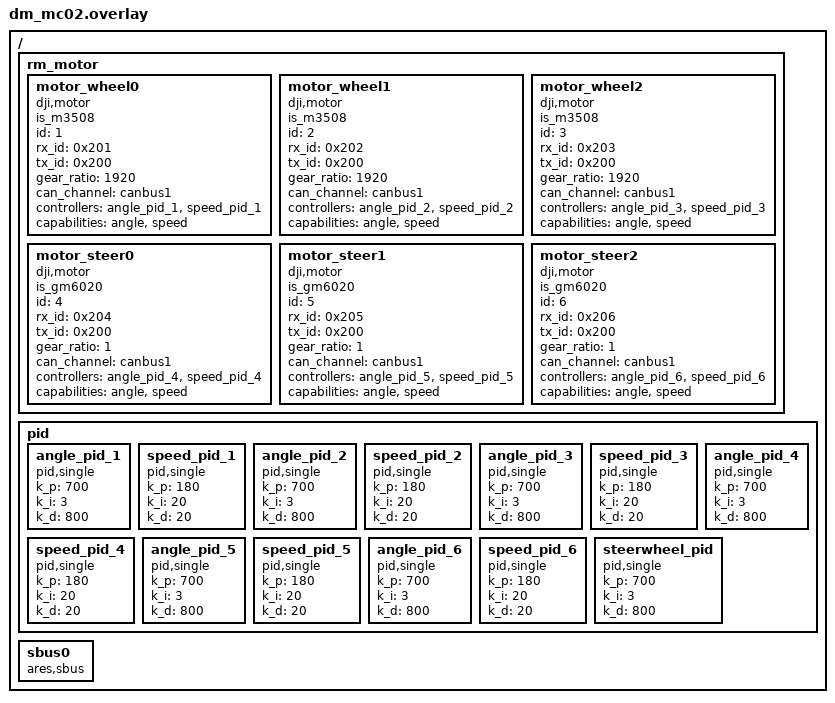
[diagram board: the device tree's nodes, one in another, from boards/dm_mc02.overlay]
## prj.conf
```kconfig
# 启用线程分析器
CONFIG_THREAD_ANALYZER=y
CONFIG_THREAD_ANALYZER_USE_LOG=y
CONFIG_THREAD_ANALYZER_USE_PRINTK=n
CONFIG_THREAD_NAME=y
# CONFIG_THREAD_ANALYZER_AUTO=y
# CONFIG_THREAD_ANALYZER_AUTO_INTERVAL=5
CONFIG_THREAD_ANALYZER_LOG_LEVEL_INF=y
CONFIG_THREAD_ANALYZER_AUTO_SEPARATE_CORES=n

# 启用 Shell 支持
CONFIG_SHELL=n
CONFIG_SHELL_BACKENDS=n
CONFIG_SHELL_BACKEND_SERIAL=n

# 启用 UART 控制台
CONFIG_UART_CONSOLE=y

# 禁用 SEGGER RTT
CONFIG_USE_SEGGER_RTT=n

# 启用事件支持
CONFIG_EVENTS=y

# 启用控制台支持
CONFIG_CONSOLE=y

# 启用日志系统
CONFIG_LOG=y
CONFIG_LOG_MODE_IMMEDIATE=y
CONFIG_LOG_PRINTK=y
CONFIG_LOG_BACKEND_UART=y
# CONFIG_LOG_MODE_IMMEDIATE=y

# 启用串行支持
CONFIG_SERIAL=y

# 禁用优化
CONFIG_NO_OPTIMIZATIONS=y

# 启用驱动
CONFIG_MOTOR=y
CONFIG_MOTOR_DJI=y
CONFIG_MOTOR_LOG_LEVEL=4
CONFIG_CAN=y
CONFIG_MOTOR_INIT_PRIORITY=90

CONFIG_ARES=y
CONFIG_ARES_SBUS=y
CONFIG_EKF_LIB=y
CONFIG_VOFA_LIB=y

CONFIG_AUTO_PROBE_GYRO_BIAS=y

# use ASYNC uart API
CONFIG_SERIAL=y
CONFIG_UART_ASYNC_API=y
CONFIG_UART_INTERRUPT_DRIVEN=y

CONFIG_DMA=y
CONFIG_DMA_STM32=y  # STM32 DMA 驱动
CONFIG_UART_STM32=y # STM32 UART 驱动
# CONFIG_STM32_UART_DMA=y

# CONFIG_HAS_STM32CUBE=y
# CONFIG_USE_STM32_HAL_DMA=y
CONFIG_SPI=y
CONFIG_SPI_STM32=y

CONFIG_CMSIS_DSP=y
CONFIG_CMSIS_DSP_MATRIX=y
CONFIG_CMSIS_DSP_CONTROLLER=y
CONFIG_CMSIS_DSP_FASTMATH=y

CONFIG_ZBUS=y
CONFIG_ZBUS_LOG_LEVEL_OFF=y
CONFIG_ZBUS_MSG_SUBSCRIBER=y
CONFIG_ZBUS_RUNTIME_OBSERVERS=y

CONFIG_CHASSIS=y

CONFIG_MAIN_STACK_SIZE=2048
```

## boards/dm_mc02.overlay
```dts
/ {

	rm_motor {
		motor_wheel0: motor_wheel0{
			compatible = "dji,motor";
            is_m3508;
			id = <1>;
            rx_id = <0x201>;
            tx_id = <0x200>;
			gear_ratio = <1920>;
			status = "okay";
			can_channel = <&canbus1>;
			controllers = <&angle_pid_1 &speed_pid_1>;
			capabilities = "angle", "speed";
		};

		motor_wheel1: motor_wheel1{
			compatible = "dji,motor";
            is_m3508;
			id = <2>;
            rx_id = <0x202>;
            tx_id = <0x200>;
			gear_ratio = <1920>;
			status = "okay";
			can_channel = <&canbus1>;
			controllers = <&angle_pid_2 &speed_pid_2>;
			capabilities = "angle", "speed";
		};

		motor_wheel2: motor_wheel2{
			compatible = "dji,motor";
            is_m3508;
			id = <3>;
            rx_id = <0x203>;
            tx_id = <0x200>;
			gear_ratio = <1920>;
			status = "okay";
			can_channel = <&canbus1>;
			controllers = <&angle_pid_3 &speed_pid_3>;
			capabilities = "angle", "speed";
		};

		motor_steer0: motor_steer0{
			compatible = "dji,motor";
			is_gm6020;
			id = <4>;
			rx_id = <0x204>;
			tx_id = <0x200>;
			gear_ratio = <1>;
			status = "okay";
			can_channel = <&canbus1>;
			controllers = <&angle_pid_4 &speed_pid_4>;
			capabilities = "angle", "speed";
		};

		motor_steer1: motor_steer1{
			compatible = "dji,motor";
			is_gm6020;
			id = <5>;
			rx_id = <0x205>;
			tx_id = <0x200>;
			gear_ratio = <1>;
			status = "okay";
			can_channel = <&canbus1>;
			controllers = <&angle_pid_5 &speed_pid_5>;
			capabilities = "angle", "speed";
		};

		motor_steer2: motor_steer2{
			compatible = "dji,motor";
			is_gm6020;
			id = <6>;
			rx_id = <0x206>;
			tx_id = <0x200>;
			gear_ratio = <1>;
			status = "okay";
			can_channel = <&canbus1>;
			controllers = <&angle_pid_6 &speed_pid_6>;
			capabilities = "angle", "speed";
		};
	};

	pid {
		angle_pid_1: angle_pid_1 {
			#controller-cells = <0>;
			compatible = "pid,single";
			k_p = <700>;
			k_i = <3>;
			k_d = <800>;
		};
		speed_pid_1: speed_pid_1 {
			#controller-cells = <0>;
			compatible = "pid,single";
			k_p = <180>;
			k_i = <20>;
			k_d = <20>;
		};
		angle_pid_2: angle_pid_2 {
			#controller-cells = <0>;
			compatible = "pid,single";
			k_p = <700>;
			k_i = <3>;
			k_d = <800>;
		};
		speed_pid_2: speed_pid_2 {
			#controller-cells = <0>;
			compatible = "pid,single";
			k_p = <180>;
			k_i = <20>;
			k_d = <20>;
		};
		angle_pid_3: angle_pid_3 {
			#controller-cells = <0>;
			compatible = "pid,single";
			k_p = <700>;
			k_i = <3>;
			k_d = <800>;
		};
		speed_pid_3: speed_pid_3 {
			#controller-cells = <0>;
			compatible = "pid,single";
			k_p = <180>;
			k_i = <20>;
			k_d = <20>;
		};

		angle_pid_4: angle_pid_4 {
			#controller-cells = <0>;
			compatible = "pid,single";
			k_p = <700>;
			k_i = <3>;
			k_d = <800>;
		};
		speed_pid_4: speed_pid_4 {
			#controller-cells = <0>;
			compatible = "pid,single";
			k_p = <180>;
			k_i = <20>;
			k_d = <20>;
		};
		angle_pid_5: angle_pid_5 {
			#controller-cells = <0>;
			compatible = "pid,single";
			k_p = <700>;
			k_i = <3>;
			k_d = <800>;
		};
		speed_pid_5: speed_pid_5 {
			#controller-cells = <0>;
			compatible = "pid,single";
			k_p = <180>;
			k_i = <20>;
			k_d = <20>;
		};
		angle_pid_6: angle_pid_6 {
			#controller-cells = <0>;
			compatible = "pid,single";
			k_p = <700>;
			k_i = <3>;
			k_d = <800>;
		};
		speed_pid_6: speed_pid_6 {
			#controller-cells = <0>;
			compatible = "pid,single";
			k_p = <180>;
			k_i = <20>;
			k_d = <20>;
		};

		steerwheel_pid: steerwheel_pid {
			#controller-cells = <0>;
			compatible = "pid,single";
			k_p = <700>;
			k_i = <3>;
			k_d = <800>;
		};
	};

	sbus0: sbus0 {
		compatible = "ares,sbus";
		status = "okay";
	};
};
```

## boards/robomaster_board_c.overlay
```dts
/ {
	chassis: chassis {
		compatible = "ares,chassis";
		status = "okay";
		wheels = <&steerwheel3  0 2592>,
				<&steerwheel1 2245 (-1296)>,
				<&steerwheel2 (-2245) (-1296)>;
		angle-pid = <&chassis_roll_angle_pid>;
		track_angle;
	};
	steerwheel {
		steerwheel1: steerwheel1 {
			#wheel-cells = <2>;
			compatible = "ares,steerwheel";
			status = "okay";
			steer-motor = <&motor_steer0>;
			wheel-motor = <&motor_wheel0>;
			wheel-radius = "0.555";
			angle-offset = "-139.69";
		};

		steerwheel2: steerwheel2 {
			#wheel-cells = <2>;
			compatible = "ares,steerwheel";
			status = "okay";
			steer-motor = <&motor_steer1>;
			wheel-motor = <&motor_wheel1>;
			wheel-radius = "0.555";
			angle-offset = "19.69";
		};

		steerwheel3: steerwheel3 {
			#wheel-cells = <2>;
			compatible = "ares,steerwheel";
			status = "okay";
			steer-motor = <&motor_steer2>;
			wheel-motor = <&motor_wheel2>;
			wheel-radius = "0.555";
			angle-offset = "-60";
		};
	};

	rm_motor {
		motor_wheel0: motor_wheel0{
			compatible = "dji,motor";
            is_m3508;
			id = <1>;
            rx_id = <0x201>;
            tx_id = <0x200>;
			gear_ratio = "15.7647";
			status = "okay";
			can_channel = <&canbus2>;
			controllers = <&wheel_angle_pid &wheel_speed_pid>;
			capabilities = "angle", "speed";
		};

		motor_wheel1: motor_wheel1{
			compatible = "dji,motor";
            is_m3508;
			id = <2>;
            rx_id = <0x202>;
            tx_id = <0x200>;
			gear_ratio = "15.7647";
			status = "okay";
			can_channel = <&canbus2>;
			controllers = <&wheel_angle_pid &wheel_speed_pid>;
			capabilities = "angle", "speed";
		};

		motor_wheel2: motor_wheel2{
			compatible = "dji,motor";
            is_m3508;
			id = <3>;
            rx_id = <0x203>;
            tx_id = <0x200>;
			gear_ratio = "15.7647";
			status = "okay";
			can_channel = <&canbus2>;
			controllers = <&wheel_angle_pid &wheel_speed_pid>;
			capabilities = "angle", "speed";
		};

		motor_steer0: motor_steer0{
			compatible = "dji,motor";
			is_gm6020;
			id = <5>;
			rx_id = <0x209>;
			tx_id = <0x2FF>;
			gear_ratio = "1.0";
			status = "okay";
			can_channel = <&canbus2>;
			controllers = <&steer_angle_pid &steer_speed_pid>;
			capabilities = "angle", "speed";
		};

		motor_steer1: motor_steer1{
			compatible = "dji,motor";
			is_gm6020;
			id = <6>;
			rx_id = <0x20A>;
			tx_id = <0x2FF>;
			gear_ratio = "1.0";
			status = "okay";
			can_channel = <&canbus2>;
			controllers = <&steer_angle_pid &steer_speed_pid>;
			capabilities = "angle", "speed";
		};

		motor_steer2: motor_steer2{
			compatible = "dji,motor";
			is_gm6020;
			id = <7>;
			rx_id = <0x20B>;
			tx_id = <0x2FF>;
			gear_ratio = "1.0";
			status = "okay";
			can_channel = <&canbus2>;
			controllers = <&steer_angle_pid &steer_speed_pid>;
			capabilities = "angle", "speed";
		};
	};

	pid {
		wheel_speed_pid: wheel_speed_pid {
			#controller-cells = <0>;
			compatible = "pid,single";
			k_p = "2.65";
			k_d = "60";
			detri_lpf = "0.985";
		};

		wheel_angle_pid: wheel_angle_pid {
			#controller-cells = <0>;
			compatible = "pid,single";
			k_p = "3";
			k_d = "320";
			detri_lpf = "0.985";
		};

		steer_speed_pid: steer_speed_pid {
			#controller-cells = <0>;
			compatible = "pid,single";
			k_p = "0.0195";
			k_d = "4.85";
			detri_lpf = "0.95";
		};

		steer_angle_pid: steer_angle_pid {
			#controller-cells = <0>;
			compatible = "pid,single";
			k_p = "1.2";
			k_d = "0";
			detri_lpf = "0.9985";
		};

		chassis_roll_angle_pid: chassis_roll_angle_pid {
			#controller-cells = <0>;
			compatible = "pid,single";
			k_p = "0.33";
			k_d = "3";
		};
	};
	
	sbus0: sbus0 {
		compatible = "ares,sbus";
		status = "okay";
	};
};
```

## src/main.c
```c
/*
 * Copyright (c) 2024 ttwards <12411711@mail.sustech.edu.cn>
 *
 * SPDX-License-Identifier: Apache-2.0
 */

#include <math.h>
#include <stddef.h>
#include <stdint.h>
#include <string.h>
#include <zephyr/device.h>
#include <zephyr/logging/log.h>
#include <zephyr/kernel.h>
#include <zephyr/drivers/motor.h>
#include <zephyr/drivers/sbus.h>
#include <ares/board/init.h>
#include <ares/ekf/imu_task.h>
#include <ares/interface/usb/usb_bulk.h>
#include <ares/protocol/dual/dual_protocol.h>
#include <ares/ares_comm.h>
#include "ares/ekf/QuaternionEKF.h"
#include "devices.h"
#include <zephyr/zbus/zbus.h>
#include <zephyr/drivers/chassis.h>

LOG_MODULE_REGISTER(main, LOG_LEVEL_DBG);

#ifndef PI
#define PI 3.14159265f
#endif

float steermotor1_angle = 0;
float steermotor2_angle = 0;
float steermotor3_angle = 0;

float steermotor1_speed = 0;
float steermotor2_speed = 0;
float steermotor3_speed = 0;

int sbus_get_bool(const struct device *sbus, int channel)
{
	sbus_get_digit(sbus, channel);
	return ((int)sbus_get_percent(sbus, channel)) > 0.5;
}

/* CAN Feedback to console*/
void console_feedback(void *arg1, void *arg2, void *arg3)
{
	float angle = 0;

	while (1) {
		angle += sbus_get_percent(sbus, 0) * 5;
		angle = fmodf(angle, 360);
		float X = sbus_get_percent(sbus, 3);
		float Y = sbus_get_percent(sbus, 1);

		// 计算摇杆角度
		// Calculate joystick angle in degrees
		float joystick_angle = atan2f(Y, X) * 180.0f / PI;

		float percentage = sqrtf(X * X + Y * Y) * cosf(fmodf(joystick_angle, 45));

		chassis_set_speed(chassis, X * 3, Y * 3);
		chassis_set_gyro(chassis, -sbus_get_percent(sbus, 0) * 10.0f);
		// chassis_set_angle(2wchassis, angle);

		k_msleep(20);
	}
}
K_THREAD_DEFINE(feedback_thread, 1536, console_feedback, NULL, NULL, NULL, -1, 0, 100);

int pub_cnt = 0;

void Sensor_update_cb(QEKF_INS_t *QEKF)
{
	struct pos_data pos = {0};
	pos.Yaw = QEKF->Yaw;
	pos.accel[0] = QEKF->Accel[X];
	pos.accel[1] = QEKF->Accel[Y];
	pos.accel[2] = QEKF->Accel[Z];
	if (pub_cnt++ % 20 == 0) {
		chassis_update_sensor(chassis, &pos);
	}
}

int main(void)
{
	board_init();

	struct JFData *data = jf_send_init(uart_dev, 50);

	jf_channel_add(data, &QEKF_INS.q[0], PTR_FLOAT);
	jf_channel_add(data, &QEKF_INS.q[1], PTR_FLOAT);
	jf_channel_add(data, &QEKF_INS.q[2], PTR_FLOAT);
	jf_channel_add(data, &QEKF_INS.q[3], PTR_FLOAT);

	jf_channel_add(data, &QEKF_INS.Gyro[0], PTR_FLOAT);
	jf_channel_add(data, &QEKF_INS.Gyro[1], PTR_FLOAT);
	jf_channel_add(data, &QEKF_INS.Gyro[2], PTR_FLOAT);

	jf_channel_add(data, &QEKF_INS.GyroBias[X], PTR_FLOAT);
	jf_channel_add(data, &QEKF_INS.GyroBias[Y], PTR_FLOAT);
	jf_channel_add(data, &QEKF_INS.GyroBias[Z], PTR_FLOAT);

	k_sleep(K_MSEC(50));
	IMU_Sensor_trig_init(accel_dev, gyro_dev);

	IMU_Sensor_set_update_cb(Sensor_update_cb);

	chassis_set_angle(chassis, 0);

	while (1) {
		k_sleep(K_MSEC(500));
	}
}
```
